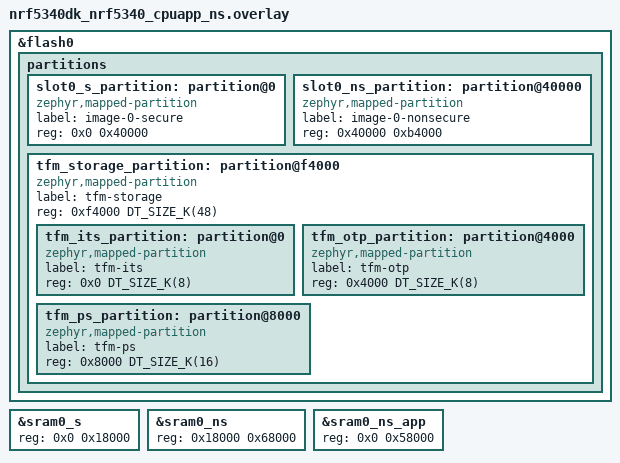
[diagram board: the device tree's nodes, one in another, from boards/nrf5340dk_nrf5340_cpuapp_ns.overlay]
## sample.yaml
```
sample:
  description: Wi-Fi Fundamentals Course by Nordic Developer Academy (https://academy.nordicsemi.com/)
  name: Wi-Fi Fundamentals Course - Lesson 3 Exercise 1 
  
common: 
    sysbuild: true
    build_only: true
    skip: true
    
tests:
  wifi_fund.l3.e1.nrf5340dk: 
    extra_args: SHIELD=nrf7002ek
    integration_platforms: 
      - nrf5340dk/nrf5340/cpuapp/ns
    platform_allow:
      - nrf5340dk/nrf5340/cpuapp/ns
  
  wifi_fund.l3.e1.nrf7002dk:
    integration_platforms: 
      - nrf7002dk/nrf5340/cpuapp/ns
    platform_allow:
      - nrf7002dk/nrf5340/cpuapp/ns
```

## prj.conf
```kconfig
#
# Copyright (c) 2023 Nordic Semiconductor ASA
#
# SPDX-License-Identifier: LicenseRef-Nordic-5-Clause
#

# Wi-Fi
CONFIG_WIFI=y
CONFIG_WIFI_NM_WPA_SUPPLICANT=y

CONFIG_NRF70_RX_NUM_BUFS=16
CONFIG_NRF70_MAX_TX_AGGREGATION=4

# Wi-Fi credentials
CONFIG_WIFI_CREDENTIALS=y
CONFIG_WIFI_CREDENTIALS_STATIC=n

# Networking Management API
CONFIG_NET_MGMT=y
CONFIG_NET_MGMT_EVENT=y
CONFIG_NET_MGMT_EVENT_INFO=y
CONFIG_NET_MGMT_EVENT_QUEUE_TIMEOUT=5000
CONFIG_NET_CONNECTION_MANAGER=y
CONFIG_NET_CONNECTION_MANAGER_MONITOR_STACK_SIZE=5200
CONFIG_L2_WIFI_CONNECTIVITY=y

# Support for shell commands
CONFIG_SHELL=y
CONFIG_NET_L2_WIFI_SHELL=y
CONFIG_WIFI_CREDENTIALS_SHELL=y
CONFIG_SHELL_STACK_SIZE=5200

# Logging
CONFIG_LOG=y

# DK library
CONFIG_DK_LIBRARY=y

# System settings
CONFIG_NEWLIB_LIBC=y
CONFIG_NEWLIB_LIBC_NANO=n

# Networking
# STEP 1.1 Configure the Zephyr networking API


# STEP 1.2 - Enable the relevant networking configurations


# Memory
CONFIG_SYSTEM_WORKQUEUE_STACK_SIZE=4096
CONFIG_MAIN_STACK_SIZE=5200



# STEP 1.3 - Configure network parameters
```

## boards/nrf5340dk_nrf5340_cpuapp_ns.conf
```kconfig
CONFIG_WIFI_CREDENTIALS_BACKEND_PSA=y
CONFIG_TFM_PROFILE_TYPE_MEDIUM=y
CONFIG_PM_PARTITION_SIZE_TFM_SRAM=0x18000
```

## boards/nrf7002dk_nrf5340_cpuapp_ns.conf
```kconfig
# UART1 is used for TF-M logging should be disabled
CONFIG_TFM_SECURE_UART=n
CONFIG_TFM_LOG_LEVEL_SILENCE=y

CONFIG_WIFI_CREDENTIALS_BACKEND_PSA=y
CONFIG_TFM_PROFILE_TYPE_MEDIUM=y
CONFIG_PM_PARTITION_SIZE_TFM_SRAM=0x18000
```

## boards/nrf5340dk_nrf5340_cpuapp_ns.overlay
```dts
/*
 * Copyright (c) 2026 Nordic Semiconductor ASA
 *
 * SPDX-License-Identifier: LicenseRef-Nordic-5-Clause
 */

/delete-node/ &boot_partition;
/delete-node/ &slot0_partition;
/delete-node/ &slot1_partition;
/delete-node/ &tfm_its_partition;
/delete-node/ &tfm_otp_partition;
/delete-node/ &tfm_ps_partition;
/delete-node/ &storage_partition;

&flash0 {
	partitions {
		slot0_s_partition: partition@0 {
			compatible = "zephyr,mapped-partition";
			label = "image-0-secure";
			reg = <0x0 0x40000>;
		};

		slot0_ns_partition: partition@40000 {
			compatible = "zephyr,mapped-partition";
			label = "image-0-nonsecure";
			reg = <0x40000 0xb4000>;
		};

		tfm_storage_partition: partition@f4000 {
			compatible = "zephyr,mapped-partition";
			label = "tfm-storage";
			reg = <0xf4000 DT_SIZE_K(48)>;
			ranges = <0x0 0xf4000 DT_SIZE_K(48)>;
			#address-cells = <1>;
			#size-cells = <1>;

			tfm_its_partition: partition@0 {
				compatible = "zephyr,mapped-partition";
				label = "tfm-its";
				reg = <0x0 DT_SIZE_K(8)>;
			};

			tfm_otp_partition: partition@4000 {
				compatible = "zephyr,mapped-partition";
				label = "tfm-otp";
				reg = <0x4000 DT_SIZE_K(8)>;
			};

			tfm_ps_partition: partition@8000 {
				compatible = "zephyr,mapped-partition";
				label = "tfm-ps";
				reg = <0x8000 DT_SIZE_K(16)>;
			};
		};
	};
};

&sram0_s {
	reg = <0x0 0x18000>;
};

&sram0_ns {
	reg = <0x18000 0x68000>;
	ranges = <0x0 0x18000 0x68000>;
};

&sram0_ns_app {
	reg = <0x0 0x58000>;
};
```

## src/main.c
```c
/*
 * Copyright (c) 2023 Nordic Semiconductor ASA
 *
 * SPDX-License-Identifier: LicenseRef-Nordic-5-Clause
 */

#include <errno.h>
#include <stddef.h>
#include <string.h>
#include <stdio.h>
#include <zephyr/kernel.h>
#include <zephyr/types.h>
#include <zephyr/logging/log.h>

#include <dk_buttons_and_leds.h>

#include <zephyr/net/net_mgmt.h>
#include <zephyr/net/wifi_mgmt.h>
#include <zephyr/net/wifi_credentials.h>

/* STEP 2 - Include the header file for the socket API */ 


LOG_MODULE_REGISTER(Lesson3_Exercise1, LOG_LEVEL_INF);

#define EVENT_MASK (NET_EVENT_L4_CONNECTED | NET_EVENT_L4_DISCONNECTED)

/* STEP 3 - Define the hostname and port for the echo server */
			

#define MESSAGE_SIZE 256 
#define MESSAGE_TO_SEND "Hello from nRF70 Series"
#define SSTRLEN(s) (sizeof(s) - 1)

static struct net_mgmt_event_callback mgmt_cb;
static bool connected;
static K_SEM_DEFINE(run_app, 0, 1);

/* STEP 4.1 - Declare the structure for the socket and server address */


/* STEP 4.2 - Declare the buffer for receiving from server */


static void net_mgmt_event_handler(struct net_mgmt_event_callback *cb,
			  uint64_t mgmt_event, struct net_if *iface)
{
	if ((mgmt_event & EVENT_MASK) != mgmt_event) {
		return;
	}
	if (mgmt_event == NET_EVENT_L4_CONNECTED) {
		LOG_INF("Network connected");
		connected = true;
		dk_set_led_on(DK_LED1);
		k_sem_give(&run_app);
		return;
	}
	if (mgmt_event == NET_EVENT_L4_DISCONNECTED) {
		if (connected == false) {
			LOG_INF("Waiting for network to be connected");
		} else {
			dk_set_led_off(DK_LED1);
			LOG_INF("Network disconnected");
			connected = false;
		}
		k_sem_reset(&run_app);
		return;
	}
}

static int server_resolve(void)
{
	/* STEP 5.1 - Call getaddrinfo() to get the IP address of the echo server */


	/* STEP 5.2 - Retrieve the relevant information from the result structure */


	/* STEP 5.3 - Convert the address into a string and print it */

	
	/* STEP 5.4 - Free the memory allocated for result */


	return 0;
}

static int server_connect(void)
{
	int err;
	/* STEP 6 - Create a UDP socket */


	/* STEP 7 - Connect the socket to the server */


	return 0;
}

static void button_handler(uint32_t button_state, uint32_t has_changed)
{
	/* STEP 8 - Send a message every time button 1 is pressed */

}

int main(void)
{
	int received;

	if (dk_leds_init() != 0) {
		LOG_ERR("Failed to initialize the LED library");
	}

	/* Sleep to allow initialization of Wi-Fi driver */
	k_sleep(K_SECONDS(1));

	net_mgmt_init_event_callback(&mgmt_cb, net_mgmt_event_handler, EVENT_MASK);
	net_mgmt_add_event_callback(&mgmt_cb);

	LOG_INF("Waiting to connect to Wi-Fi");
	k_sem_take(&run_app, K_FOREVER);

	if (dk_buttons_init(button_handler) != 0) {
		LOG_ERR("Failed to initialize the buttons library");
	}

	/* STEP 9 - Resolve the server name and connect to the server */


	LOG_INF("Press button 1 on your DK to send your message");

	while (1) {
		/* STEP 10 - Listen for incoming messages */

			
	}
	zsock_close(sock);
	return 0;
}
```
